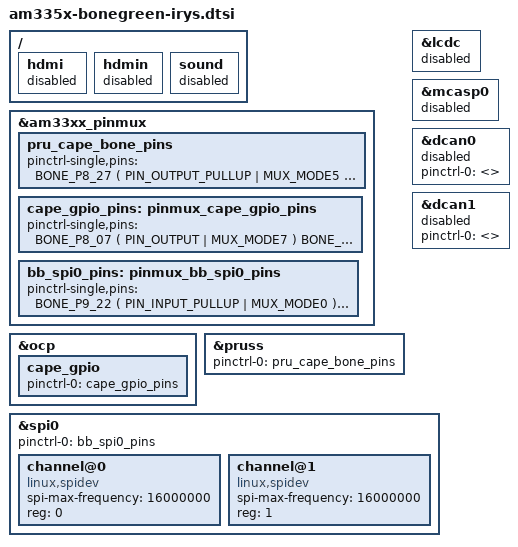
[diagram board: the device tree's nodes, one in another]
/*
 * Copyright (C) 2015 Texas Instruments Incorporated - http://www.ti.com/
 *
 * This program is free software; you can redistribute it and/or modify
 * it under the terms of the GNU General Public License version 2 as
 * published by the Free Software Foundation.
 */

&am33xx_pinmux {
	pru_cape_bone_pins: pru_cape_bone_pins {
		pinctrl-single,pins = <
			BONE_P8_27 ( PIN_OUTPUT_PULLUP | MUX_MODE5 ) // gpio2_11, Enable
			BONE_P8_28 ( PIN_OUTPUT_PULLUP | MUX_MODE5 ) // gpio2_10, M0
			BONE_P8_29 ( PIN_OUTPUT_PULLUP | MUX_MODE5 ) // gpio2_09, M1
			BONE_P8_30 ( PIN_OUTPUT_PULLUP | MUX_MODE5 ) // gpio2_08, M2
			BONE_P8_43 ( PIN_OUTPUT_PULLUP | MUX_MODE5 ) // gpio2_12, Left Dir
			BONE_P8_44 ( PIN_OUTPUT_PULLUP | MUX_MODE5 ) // gpio2_13, Left Step
			BONE_P8_45 ( PIN_OUTPUT_PULLUP | MUX_MODE5 ) // gpio2_06, Right Dir
			BONE_P8_46 ( PIN_OUTPUT_PULLUP | MUX_MODE5 ) // gpio2_07, Right Step
		>;
	};

	cape_gpio_pins: pinmux_cape_gpio_pins {
		pinctrl-single,pins = <
			// TOF enables
			BONE_P8_07 ( PIN_OUTPUT | MUX_MODE7 ) // gpio2_02, /sys/class/gpio/gpio66
			BONE_P8_08 ( PIN_OUTPUT | MUX_MODE7 ) // gpio2_03, /sys/class/gpio/gpio67
			BONE_P8_09 ( PIN_OUTPUT | MUX_MODE7 ) // gpio2_05, /sys/class/gpio/gpio69
			BONE_P9_14 ( PIN_OUTPUT | MUX_MODE7 ) // gpio1_18, .../gpio50
			BONE_P9_16 ( PIN_OUTPUT | MUX_MODE7 ) // gpio1_19, .../gpio51

			// DWM1000 enable and IRQ
			BONE_P9_27 ( PIN_OUTPUT | MUX_MODE7 ) // gpio3_19, .../gpio115
			// BONE_P9_41B ( PIN_INPUT | MUX_MODE7 ) // gpio3_20, .../gpio116
			BONE_P9_41A ( PIN_INPUT | MUX_MODE7 ) // gpio0_20, .../gpio20
		>;
	};

	bb_spi0_pins: pinmux_bb_spi0_pins {
		pinctrl-single,pins = <
			BONE_P9_22 ( PIN_INPUT_PULLUP | MUX_MODE0 ) // SCLK
			BONE_P9_21 ( PIN_INPUT_PULLUP | MUX_MODE0 ) // MISO
			BONE_P9_18 ( PIN_OUTPUT_PULLUP | MUX_MODE0 ) // MOSI
			BONE_P9_17 ( PIN_OUTPUT_PULLUP | MUX_MODE0 ) // CS0
		>;
	};
};

&ocp {
	cape_gpio {
		status = "okay";
		pinctrl-names = "default";
		pinctrl-0 = <&cape_gpio_pins>;
	};
};

&pruss {
	pinctrl-names = "default";
	pinctrl-0 = <&pru_cape_bone_pins>;
};

&lcdc {
	status = "disabled";
};

&mcasp0 {
	status = "disabled";
};

&dcan0 {
	pinctrl-0 = <>;
	status = "disabled";
};

&dcan1 {
	pinctrl-0 = <>;
	status = "disabled";
};

&spi0 {
	pinctrl-names = "default";
	pinctrl-0 = <&bb_spi0_pins>;
	#address-cells = <1>;
	#size-cells = <0>;

	channel@0 {
		#address-cells = <1>;
		#size-cells = <0>;
		compatible = "linux,spidev";
		spi-max-frequency = <16000000>;
		reg = <0>;
	};

	channel@1 {
		#address-cells = <1>;
		#size-cells = <0>;
		compatible = "linux,spidev";
		spi-max-frequency = <16000000>;
		reg = <1>;
	};
};

/{
	hdmi {
		status = "disabled";
	};

	hdmin {
		status = "disabled";
	};

	sound {
		status = "disabled";
	};
};
